# STM32N647 register map
File version: 1.0
CPU: CM55 r0p1, little endian, no MPU, FPU, vendor SysTick, 8 interrupt priority bits
Registers are 32-bit, read-write, reset 0x0 unless marked. A register's access mark holds for its fields unless they carry their own. Offsets are from the block's base; [hi:lo] are bit positions; {n}, {i} and the like mark numbered series.

## DCMI — Digital camera interface
Base 0x48028400
Same registers: DCMI_S 0x58028400
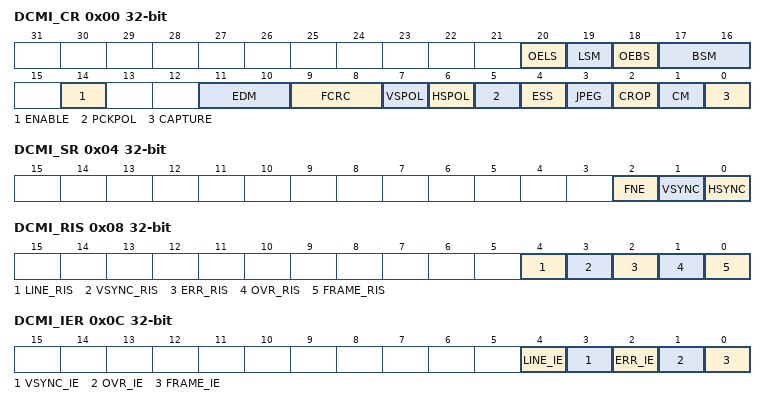
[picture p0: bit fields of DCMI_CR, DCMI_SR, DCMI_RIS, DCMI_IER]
0x00 DCMI_CR — DCMI control register
  [20] OELS — Odd/Even Line Select (Line Select Start)
    0=Interface captures first line after the frame start, second one being dropped; 1=Interface captures second line from the frame start, first one being dropped
  [19] LSM — Line Select mode
    0=Interface captures all received lines; 1=Interface captures one line out of two
  [18] OEBS — Odd/Even Byte Select (Byte Select Start)
    0=Interface captures first data (byte or double byte) from the frame/line start, second one being dropped; 1=Interface captures second data (byte or double byte) from the frame/line start, first one being dropped
  [17:16] BSM — Byte Select mode
    0=Interface captures all received data; 1=Interface captures every other byte from the received data; 2=Interface captures one byte out of four; 3=Interface captures two bytes out of four
  [14] ENABLE — DCMI enable
    0=DCMI disabled; 1=DCMI enabled
  [11:10] EDM — Extended data mode
    0=Interface captures 8-bit data on every pixel clock; 1=Interface captures 10-bit data on every pixel clock; 2=Interface captures 12-bit data on every pixel clock; 3=Interface captures 14-bit data on every pixel clock
  [9:8] FCRC — Frame capture rate control
    0=All frames are captured; 1=Every alternate frame captured (50% bandwidth reduction); 2=One frame out of four captured (75% bandwidth reduction)
  [7] VSPOL — Vertical synchronization polarity
    0=DCMI_VSYNC active low; 1=DCMI_VSYNC active high
  [6] HSPOL — Horizontal synchronization polarity
    0=DCMI_HSYNC active low; 1=DCMI_HSYNC active high
  [5] PCKPOL — Pixel clock polarity
    0=Falling edge active; 1=Rising edge active
  [4] ESS — Embedded synchronization select
    0=Hardware synchronization data capture (frame/line start/stop) is synchronized with the DCMI_HSYNC/DCMI_VSYNC signals; 1=Embedded synchronization data capture is synchronized with synchronization codes embedded in the data flow
  [3] JPEG — JPEG format
    0=Uncompressed video format; 1=This bit is used for JPEG data transfers. The DCMI_HSYNC signal is used as data enable. The crop and embedded synchronization features (ESS bit) cannot be used in this mode.
  [2] CROP — Crop feature
    0=The full image is captured. In this case the total number of bytes in an image frame must be a multiple of four.; 1=Only the data inside the window specified by the crop register is captured. If the size of the crop window exceeds the picture size, then only the picture size is captured.
  [1] CM — Capture mode
    0=Continuous grab mode - The received data are transferred into the destination memory through the DMA. The buffer location and mode (linear or circular buffer) is controlled through the system DMA.; 1=Snapshot mode (single frame) - Once activated, the interface waits for the start of frame and then transfers a single frame through the DMA. At the end of the frame, the CAPTURE bit is automatically reset.
  [0] CAPTURE — Capture enable
    0=Capture disabled; 1=Capture enabled
0x04 DCMI_SR ro — DCMI status register
  [2] FNE — FIFO not empty
    1=FIFO contains valid data; 0=FIFO empty
  [1] VSYNC — Vertical synchronization
    0=active frame; 1=synchronization between frames
  [0] HSYNC — Horizontal synchronization
    0=active line; 1=synchronization between lines
0x08 DCMI_RIS ro — DCMI raw interrupt status register
  [4] LINE_RIS — Line raw interrupt status
  [3] VSYNC_RIS — DCMI_VSYNC raw interrupt status
  [2] ERR_RIS — Synchronization error raw interrupt status
    0=No synchronization error detected; 1=Embedded synchronization characters are not received in the correct order
  [1] OVR_RIS — Overrun raw interrupt status
    0=No data buffer overrun occurred; 1=A data buffer overrun occurred and the data FIFO is corrupted
  [0] FRAME_RIS — Capture complete raw interrupt status
    0=No new capture; 1=A frame has been captured
0x0C DCMI_IER — DCMI interrupt enable register
  [4] LINE_IE — Line interrupt enable
    0=No interrupt generation when the line is received; 1=An Interrupt is generated when a line has been completely received
  [3] VSYNC_IE — DCMI_VSYNC interrupt enable
    0=No interrupt generation; 1=An interrupt is generated on each DCMI_VSYNC transition from the inactive to the active state
  [2] ERR_IE — Synchronization error interrupt enable
    0=No interrupt generation; 1=An interrupt is generated if the embedded synchronization codes are not received in the correct order
  [1] OVR_IE — Overrun interrupt enable
    0=No interrupt generation; 1=An interrupt is generated if the DMA was not able to transfer the last data before new data (32-bit) are received
  [0] FRAME_IE — Capture complete interrupt enable
    0=No interrupt generation; 1=An interrupt is generated at the end of each received frame/crop window (in crop mode)
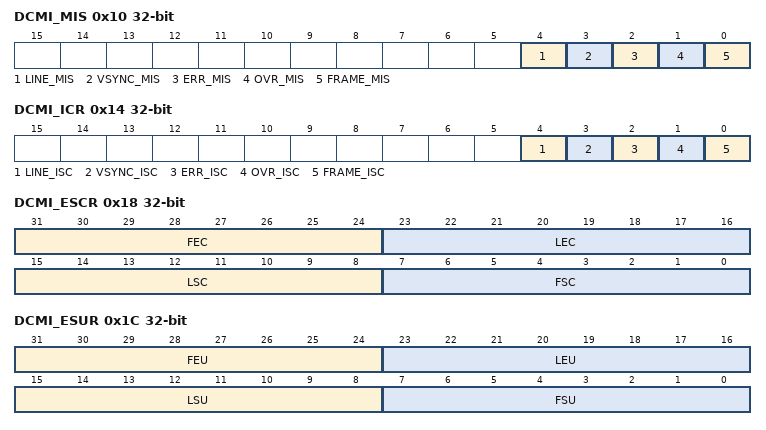
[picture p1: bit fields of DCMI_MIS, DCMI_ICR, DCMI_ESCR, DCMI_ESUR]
0x10 DCMI_MIS ro — DCMI masked interrupt status register
  [4] LINE_MIS — Line masked interrupt status
    0=No interrupt generation when the line is received; 1=An Interrupt is generated when a line has been completely received and the LINE_IE bit is set in DCMI_IER
  [3] VSYNC_MIS — VSYNC masked interrupt status
    0=No interrupt is generated on DCMI_VSYNC transitions; 1=An interrupt is generated on each DCMI_VSYNC transition from the inactive to the active state and the VSYNC_IE bit is set in DCMI_IER
  [2] ERR_MIS — Synchronization error masked interrupt status
    0=No interrupt is generated on a synchronization error; 1=An interrupt is generated if the embedded synchronization codes are not received in the correct order and the ERR_IE bit in DCMI_IER is set
  [1] OVR_MIS — Overrun masked interrupt status
    0=No interrupt is generated on overrun; 1=An interrupt is generated if the DMA was not able to transfer the last data before new data (32-bit) are received and the OVR_IE bit is set in DCMI_IER
  [0] FRAME_MIS — Capture complete masked interrupt status
    0=No interrupt is generated after a complete capture; 1=An interrupt is generated at the end of each received frame/crop window (in crop mode) and the FRAME_IE bit is set in DCMI_IER
0x14 DCMI_ICR wo — DCMI interrupt clear register
  [4] LINE_ISC — line interrupt status clear
  [3] VSYNC_ISC — Vertical Synchronization interrupt status clear
  [2] ERR_ISC — Synchronization error interrupt status clear
  [1] OVR_ISC — Overrun interrupt status clear
  [0] FRAME_ISC — Capture complete interrupt status clear
0x18 DCMI_ESCR — DCMI embedded synchronization code register
  [31:24] FEC — Frame end delimiter code
  [23:16] LEC — Line end delimiter code
  [15:8] LSC — Line start delimiter code
  [7:0] FSC — Frame start delimiter code
0x1C DCMI_ESUR — DCMI embedded synchronization unmask register
  [31:24] FEU — Frame end delimiter unmask
    0=The corresponding bit in the FEC byte in DCMI_ESCR is masked while comparing the frame end delimiter with the received data; 1=The corresponding bit in the FEC byte in DCMI_ESCR is compared while comparing the frame end delimiter with the received data
  [23:16] LEU — Line end delimiter unmask
    0=The corresponding bit in the LEC byte in DCMI_ESCR is masked while comparing the line end delimiter with the received data; 1=The corresponding bit in the LEC byte in DCMI_ESCR is compared while comparing the line end delimiter with the received data
  [15:8] LSU — Line start delimiter unmask
    0=The corresponding bit in the LSC byte in DCMI_ESCR is masked while comparing the line start delimiter with the received data; 1=The corresponding bit in the LSC byte in DCMI_ESCR is compared while comparing the line start delimiter with the received data
  [7:0] FSU — Frame start delimiter unmask
    0=The corresponding bit in the FSC byte in DCMI_ESCR is masked while comparing the frame start delimiter with the received data; 1=The corresponding bit in the FSC byte in DCMI_ESCR is compared while comparing the frame start delimiter with the received data
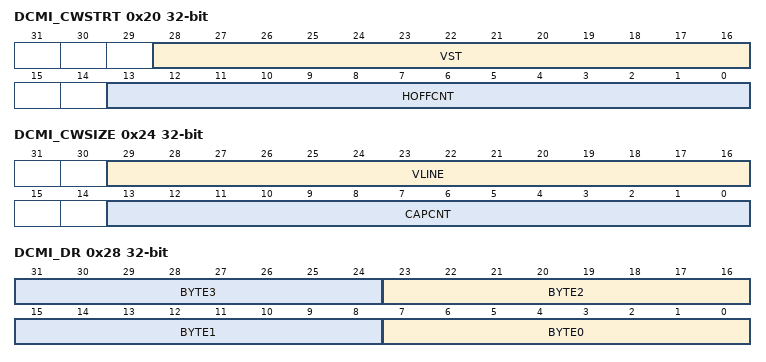
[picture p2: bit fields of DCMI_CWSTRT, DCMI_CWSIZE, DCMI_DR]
0x20 DCMI_CWSTRT — DCMI crop window start
  [28:16] VST — Vertical start line count
    0=line 1; 1=line 2; 2=line 3
  [13:0] HOFFCNT — Horizontal offset count
0x24 DCMI_CWSIZE — DCMI crop window size
  [29:16] VLINE — Vertical line count
    0=1 line; 1=2 lines; 2=3 lines
  [13:0] CAPCNT — Capture count
    0=1 pixel; 1=2 pixels; 2=3 pixels
0x28 DCMI_DR ro — DCMI data register
  [8n+7:8n] BYTE{n} (n=0..3) — Data byte {n}

## Notices in the file
Copyright (c) 2024 STMicroelectronics.
SPDX-License-Identifier: Apache-2.0
Licensed under the Apache License, Version 2.0 (the "License");
you may not use this file except in compliance with the License.
You may obtain a copy of the License at
http://www.apache.org/licenses/LICENSE-2.0
Unless required by applicable law or agreed to in writing, software
distributed under the License is distributed on an "AS IS" BASIS,
WITHOUT WARRANTIES OR CONDITIONS OF ANY KIND, either express or implied.
See the License for the specific language governing permissions and
limitations under the License.
